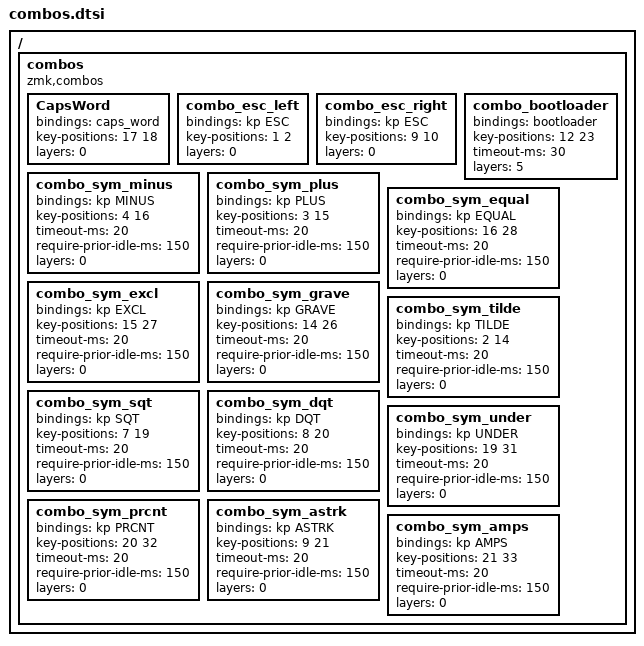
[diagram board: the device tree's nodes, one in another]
/* --- KEY ID LAYOUT --- */
// ╭──────┬──────┬──────┬──────┬──────┬──────╮  ╭──────┬──────┬──────┬──────┬──────┬──────╮
//    00     01     02     03    04      05        06     07     08     09     10     11
// ├──────┼──────┼──────┼──────┼──────┼──────┤  ├──────┼──────┼──────┼──────┼──────┼──────┤
//    12     13     14     15    16      17        18     19     20     21     22     23
// ├──────┼──────┼──────┼──────┼──────┼──────┤  ├──────┼──────┼──────┼──────┼──────┼──────┤
//    24     25     26     27    28      29        30     31     32     33     34     35
// ╰──────┴──────┴──────┼──────┼──────┼──────┤  ├──────┼──────┼──────┴──────┴──────┴──────╯
//                         36     37     38        39     40
//                      ╰──────┴──────┴──────╯  ╰──────┴──────╯

/ {
    combos {
        compatible = "zmk,combos";

        CapsWord {
            bindings = <&caps_word>;
            key-positions = <17 18>;
            layers = <0>;
        };

        combo_esc_left {
            bindings = <&kp ESC>;
            key-positions = <1 2>;
            layers = <0>;
        };

        combo_esc_right {
            bindings = <&kp ESC>;
            key-positions = <9 10>;
            layers = <0>;
        };



        combo_bootloader {
            bindings = <&bootloader>;
            key-positions = <12 23>;
            timeout-ms = <30>;
            layers = <5>;
        };


        // hillside-style symbol combos — vertical same-column pairs, BASE layer only
        combo_sym_minus { bindings = <&kp MINUS>; key-positions = <4 16>;  timeout-ms = <20>; require-prior-idle-ms = <150>; layers = <0>; }; // P+T
        combo_sym_plus  { bindings = <&kp PLUS>;  key-positions = <3 15>;  timeout-ms = <20>; require-prior-idle-ms = <150>; layers = <0>; }; // F+S
        combo_sym_equal { bindings = <&kp EQUAL>; key-positions = <16 28>; timeout-ms = <20>; require-prior-idle-ms = <150>; layers = <0>; }; // T+D
        combo_sym_excl  { bindings = <&kp EXCL>;  key-positions = <15 27>; timeout-ms = <20>; require-prior-idle-ms = <150>; layers = <0>; }; // S+C
        combo_sym_grave { bindings = <&kp GRAVE>; key-positions = <14 26>; timeout-ms = <20>; require-prior-idle-ms = <150>; layers = <0>; }; // R+X
        combo_sym_tilde { bindings = <&kp TILDE>; key-positions = <2 14>;  timeout-ms = <20>; require-prior-idle-ms = <150>; layers = <0>; }; // W+R
        combo_sym_sqt   { bindings = <&kp SQT>;   key-positions = <7 19>;  timeout-ms = <20>; require-prior-idle-ms = <150>; layers = <0>; }; // L+N
        combo_sym_dqt   { bindings = <&kp DQT>;   key-positions = <8 20>;  timeout-ms = <20>; require-prior-idle-ms = <150>; layers = <0>; }; // U+E
        combo_sym_under { bindings = <&kp UNDER>; key-positions = <19 31>; timeout-ms = <20>; require-prior-idle-ms = <150>; layers = <0>; }; // N+H
        combo_sym_prcnt { bindings = <&kp PRCNT>; key-positions = <20 32>; timeout-ms = <20>; require-prior-idle-ms = <150>; layers = <0>; }; // E+,
        combo_sym_astrk { bindings = <&kp ASTRK>; key-positions = <9 21>;  timeout-ms = <20>; require-prior-idle-ms = <150>; layers = <0>; }; // Y+I
        combo_sym_amps  { bindings = <&kp AMPS>;  key-positions = <21 33>; timeout-ms = <20>; require-prior-idle-ms = <150>; layers = <0>; }; // I+.
    };
};
